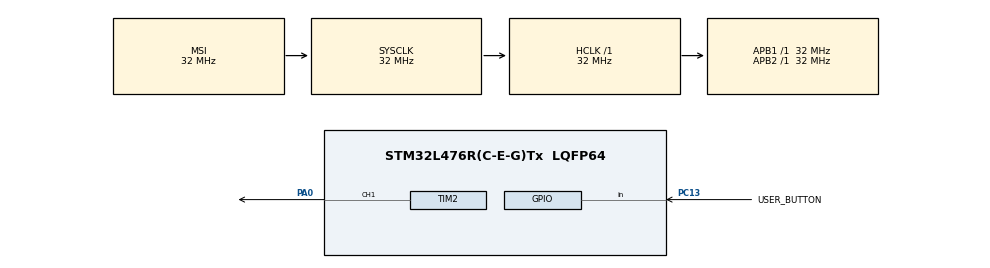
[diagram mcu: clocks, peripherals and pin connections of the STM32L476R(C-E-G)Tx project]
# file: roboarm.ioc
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Mcu.Family=STM32L4
Mcu.Name=STM32L476R(C-E-G)Tx
Mcu.Package=LQFP64
NVIC.PriorityGroup=NVIC_PRIORITYGROUP_4
PA0.Signal=S_TIM2_CH1
PC13.GPIO_Label=USER_BUTTON
PC13.Signal=GPIO_Input
ProjectManager.HeapSize=0x200
ProjectManager.StackSize=0x400
ProjectManager.TargetToolchain=STM32CubeIDE
RCC.ADCFreq_Value=128000000
RCC.AHBFreq_Value=32000000
RCC.APB1Freq_Value=32000000
RCC.APB1TimFreq_Value=32000000
RCC.APB2Freq_Value=32000000
RCC.APB2TimFreq_Value=32000000
RCC.CortexFreq_Value=32000000
RCC.HCLKFreq_Value=32000000
RCC.HSE_VALUE=8000000
RCC.HSI_VALUE=16000000
RCC.LSE_VALUE=32768
RCC.MSIClockRange=RCC_MSIRANGE_10
RCC.MSI_VALUE=32000000
RCC.SYSCLKFreq_VALUE=32000000
RCC.USBFreq_Value=128000000
RCC.VCOOutputFreq_Value=256000000
SH.S_TIM2_CH1.0=TIM2_CH1,PWM Generation1 CH1
TIM2.Channel-PWM\ Generation1\ CH1=TIM_CHANNEL_1
TIM2.Period=20000
TIM2.Prescaler=31
TIM2.Pulse-PWM\ Generation1\ CH1=1000
VP_TIM2_VS_ClockSourceINT.Mode=Internal
board=custom

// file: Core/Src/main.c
/* USER CODE BEGIN Header */
/**
  ******************************************************************************
  * @file           : main.c
  * @brief          : Main program body
  ******************************************************************************
  * @attention
  *
  * Copyright (c) 2026 STMicroelectronics.
  * All rights reserved.
  *
  * This software is licensed under terms that can be found in the LICENSE file
  * in the root directory of this software component.
  * If no LICENSE file comes with this software, it is provided AS-IS.
  *
  ******************************************************************************
  */
/* USER CODE END Header */
#include "main.h"
#include "tim.h"
#include "gpio.h"

/* USER CODE BEGIN Includes */

#include "stdbool.h"
#include "servo.h"

/* USER CODE END Includes */

/* USER CODE BEGIN PD */

#define GRABBER_ROTATION_MIN 30
#define GRABBER_ROTATION_MAX 65

/* USER CODE END PD */

void SystemClock_Config(void);

int main(void)
{

  /* MCU Configuration--------------------------------------------------------*/

  /* Reset of all peripherals, Initializes the Flash interface and the Systick. */
  HAL_Init();

  /* Configure the system clock */
  SystemClock_Config();

  /* Initialize all configured peripherals */
  MX_GPIO_Init();
  MX_TIM2_Init();

  /* Infinite loop */
  /* USER CODE BEGIN WHILE */
  servo_t servo;
  servoInit(&servo, &htim2, TIM_CHANNEL_1, SERVO_180);
  servoStart(&servo);
  servoSetRotation(&servo, GRABBER_ROTATION_MIN);
  bool open = true;

  while (1)
  {
	  if(HAL_GPIO_ReadPin(USER_BUTTON_GPIO_Port, USER_BUTTON_Pin) == GPIO_PIN_RESET) {
		  	  if(open) {
		  		  servoSetRotation(&servo, GRABBER_ROTATION_MAX);
		  		  HAL_Delay(500);
		  		  open = false;
		  	  } else {
		  		  servoSetRotation(&servo, GRABBER_ROTATION_MIN);
		  		  HAL_Delay(500);
		  		  open = true;
		  	  }
	  }
    /* USER CODE END WHILE */

  }
}

void SystemClock_Config(void)
{
  RCC_OscInitTypeDef RCC_OscInitStruct = {0};
  RCC_ClkInitTypeDef RCC_ClkInitStruct = {0};

  /** Configure the main internal regulator output voltage
  */
  if (HAL_PWREx_ControlVoltageScaling(PWR_REGULATOR_VOLTAGE_SCALE1) != HAL_OK)
  {
    Error_Handler();
  }

  /** Initializes the RCC Oscillators according to the specified parameters
  * in the RCC_OscInitTypeDef structure.
  */
  RCC_OscInitStruct.OscillatorType = RCC_OSCILLATORTYPE_MSI;
  RCC_OscInitStruct.MSIState = RCC_MSI_ON;
  RCC_OscInitStruct.MSICalibrationValue = 0;
  RCC_OscInitStruct.MSIClockRange = RCC_MSIRANGE_10;
  RCC_OscInitStruct.PLL.PLLState = RCC_PLL_NONE;
  if (HAL_RCC_OscConfig(&RCC_OscInitStruct) != HAL_OK)
  {
    Error_Handler();
  }

  /** Initializes the CPU, AHB and APB buses clocks
  */
  RCC_ClkInitStruct.ClockType = RCC_CLOCKTYPE_HCLK|RCC_CLOCKTYPE_SYSCLK
                              |RCC_CLOCKTYPE_PCLK1|RCC_CLOCKTYPE_PCLK2;
  RCC_ClkInitStruct.SYSCLKSource = RCC_SYSCLKSOURCE_MSI;
  RCC_ClkInitStruct.AHBCLKDivider = RCC_SYSCLK_DIV1;
  RCC_ClkInitStruct.APB1CLKDivider = RCC_HCLK_DIV1;
  RCC_ClkInitStruct.APB2CLKDivider = RCC_HCLK_DIV1;

  if (HAL_RCC_ClockConfig(&RCC_ClkInitStruct, FLASH_LATENCY_1) != HAL_OK)
  {
    Error_Handler();
  }
}

void Error_Handler(void)
{
  __disable_irq();
  while (1)
  {
  }
}
